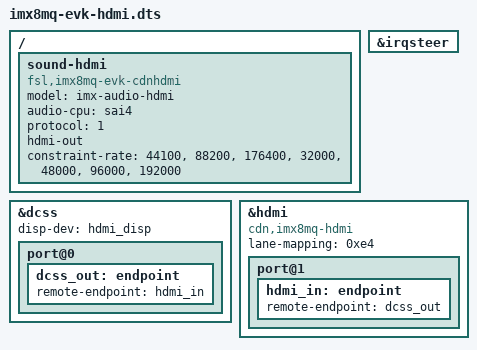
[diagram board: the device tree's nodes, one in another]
// SPDX-License-Identifier: GPL-2.0
/*
 * Copyright 2019 NXP.
 */

#include "imx8mq-evk.dts"

/ {
	sound-hdmi {
		compatible = "fsl,imx8mq-evk-cdnhdmi",
				"fsl,imx-audio-cdnhdmi";
		model = "imx-audio-hdmi";
		audio-cpu = <&sai4>;
		protocol = <1>;
		hdmi-out;
		constraint-rate = <44100>,
				<88200>,
				<176400>,
				<32000>,
				<48000>,
				<96000>,
				<192000>;
	};
};

&irqsteer {
	status = "okay";
};

&dcss {
	status = "okay";
	disp-dev = "hdmi_disp";

	port@0 {
		dcss_out: endpoint {
			remote-endpoint = <&hdmi_in>;
		};
	};
};

&hdmi {
	compatible = "cdn,imx8mq-hdmi";
	lane-mapping = <0xe4>;
	status = "okay";
	port@1 {
		hdmi_in: endpoint {
			remote-endpoint = <&dcss_out>;
		};
	};
};
